VERSION ""

NS_ :

BS_:

BU_: JETSON VCU ACU RES DYN_F DYN_R

BO_ 81 ACU_MS: 1 ACU
 SG_ Mission_Select : 0|8@1+ (1,0) [0|0] ""  JETSON

BO_ 97 JETSON_MS: 1 JETSON
 SG_ Mission_Select : 0|8@1+ (1,0) [0|0] ""  ACU

BO_ 1296 VCU_RPM: 2 VCU
 SG_ RPM : 0|16@1- (1,0) [0|6000] "RPM"  JETSON

BO_ 1280 Target_RPM: 2 JETSON
 SG_ RPM : 0|16@1- (1,0) [0|6000] "RPM"  VCU

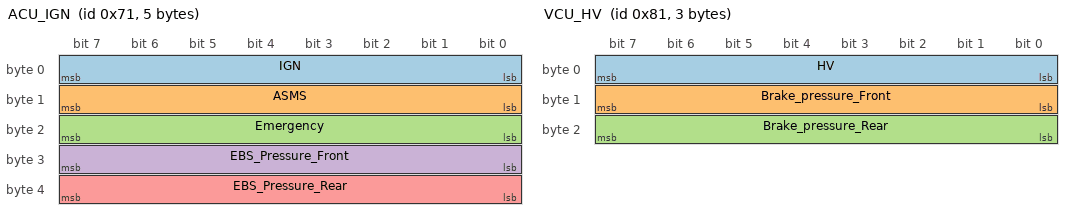
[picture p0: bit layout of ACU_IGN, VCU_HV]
BO_ 113 ACU_IGN: 5 ACU
 SG_ IGN : 0|8@1+ (1,0) [0|1] ""  VCU
 SG_ ASMS : 8|8@1+ (1,0) [0|1] ""  VCU
 SG_ Emergency : 16|8@1+ (1,0) [0|0] ""  VCU
 SG_ EBS_Pressure_Front : 24|8@1+ (10,0) [0|150] "bar" Vector__XXX
 SG_ EBS_Pressure_Rear : 32|8@1+ (10,0) [0|150] "bar" Vector__XXX

BO_ 1298 RD_JETSON: 1 ACU
 SG_ RD : 0|8@1+ (1,0) [0|0] ""  JETSON

BO_ 1282 AS_STATE: 1 JETSON
 SG_ STATE : 0|8@1+ (1,0) [0|0] ""  VCU,ACU

BO_ 129 VCU_HV: 3 VCU
 SG_ HV : 0|8@1+ (1,0) [0|0] ""  ACU
 SG_ Brake_pressure_Front : 8|8@1+ (1,0) [0|0] "" Vector__XXX
 SG_ Brake_pressure_Rear : 16|8@1+ (1,0) [0|0] "" Vector__XXX

BO_ 401 RES: 8 RES
 SG_ SIGNAL : 0|8@1+ (1,0) [0|0] ""  JETSON,ACU

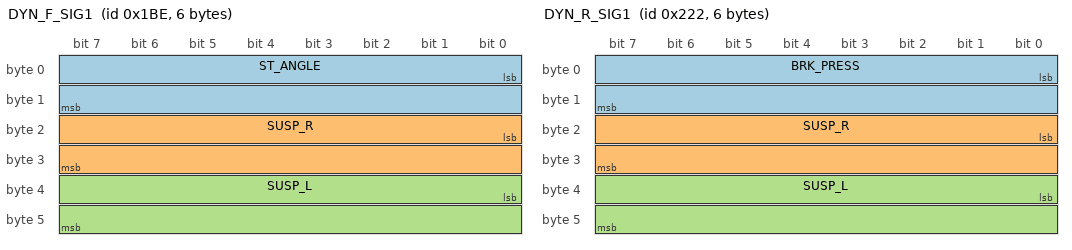
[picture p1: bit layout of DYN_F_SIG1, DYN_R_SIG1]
BO_ 446 DYN_F_SIG1: 6 DYN_F
 SG_ ST_ANGLE : 0|16@1- (10,0) [0|0] "º" Vector__XXX
 SG_ SUSP_R : 16|16@1+ (10,0) [0|0] "mm" Vector__XXX
 SG_ SUSP_L : 32|16@1+ (10,0) [0|0] "mm" Vector__XXX

BO_ 456 DYN_F_SIG2: 4 DYN_F
 SG_ SPD_LEFT : 0|16@1+ (10,0) [0|0] "km/h" Vector__XXX
 SG_ SPD_RIGHT : 16|16@1+ (10,0) [0|0] "km/h" Vector__XXX

BO_ 546 DYN_R_SIG1: 6 DYN_R
 SG_ BRK_PRESS : 0|16@1+ (10,0) [0|0] "bar" Vector__XXX
 SG_ SUSP_R : 16|16@1+ (10,0) [0|0] "mm" Vector__XXX
 SG_ SUSP_L : 32|16@1+ (10,0) [0|0] "mm" Vector__XXX

BO_ 556 DYN_R_SIG2: 4 DYN_R
 SG_ SPD_LEFT : 0|16@1+ (10,0) [0|0] "km/h" Vector__XXX
 SG_ SPD_RIGHT : 16|16@1+ (10,0) [0|0] "km/h" Vector__XXX

CM_ SG_ 113 EBS_Pressure_Front "Perdu gay";
CM_ SG_ 113 EBS_Pressure_Rear "(null)";
CM_ SG_ 1282 STATE "Regulations";
VAL_ 81 Mission_Select 0 "Manual" 1 "Acceleration" 2 "Skidpad" 3 "Trackdrive" 4 "Braketest" 5 "Inspection" 6 "Autocross" ;
VAL_ 97 Mission_Select 0 "Manual" 1 "Acceleration" 2 "Skidpadd" 3 "Trackdrive" 4 "Braketest" 5 "Inspection" 6 "Autocross" ;
VAL_ 113 IGN 0 "OFF" 1 "ON" ;
VAL_ 113 ASMS 0 "OFF" 1 "ON" ;
VAL_ 113 Emergency 1 "Emergency_ON" 0 "Emergency_OFF" ;
VAL_ 1298 RD 0 "OFF" 1 "ON" ;
VAL_ 1282 STATE 1 "OFF" 2 "Ready" 3 "Driving" 4 "Emergency" 5 "Finish" ;
VAL_ 129 HV 0 "hv off" 9 "hv on" 10 "contactor error" ;
VAL_ 401 SIGNAL 5 "GO_SIGNAL" 7 "GO_SIGNAL_2" 0 "EMERGENCY" ;
